# MSP430G2553 register map
Registers are 8-bit, read-write, reset 0x0 unless marked. A register's access mark holds for its fields unless they carry their own. Offsets are from the block's base; [hi:lo] are bit positions; {n}, {i} and the like mark numbered series.

## CALIBRATION_DATA
Base 0x000010F8
0x00 CALDCO_16MHZ — DCOCTL Calibration Data for 16MHz
0x01 CALBC1_16MHZ — BCSCTL1 Calibration Data for 16MHz
0x02 CALDCO_12MHZ — DCOCTL Calibration Data for 12MHz
0x03 CALBC1_12MHZ — BCSCTL1 Calibration Data for 12MHz
0x04 CALDCO_8MHZ — DCOCTL Calibration Data for 8MHz
0x05 CALBC1_8MHZ — BCSCTL1 Calibration Data for 8MHz
0x06 CALDCO_1MHZ — DCOCTL Calibration Data for 1MHz
0x07 CALBC1_1MHZ — BCSCTL1 Calibration Data for 1MHz

## TIMER_1_A3
Base 0x0000011E
0x00 TA1IV 16-bit — Timer1_A3 Interrupt Vector Word
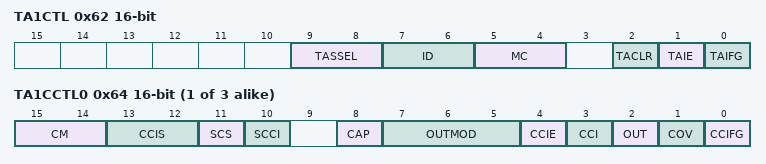
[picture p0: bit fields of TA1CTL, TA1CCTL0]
0x62 TA1CTL 16-bit — Timer1_A3 Control
  [9:8] TASSEL — Timer A clock source select 1
    0=Timer A clock source select: 0 - TACLK; 1=Timer A clock source select: 1 - ACLK; 2=Timer A clock source select: 2 - SMCLK; 3=Timer A clock source select: 3 - INCLK
  [7:6] ID — Timer A clock input divider 1
    0=Timer A input divider: 0 - /1; 1=Timer A input divider: 1 - /2; 2=Timer A input divider: 2 - /4; 3=Timer A input divider: 3 - /8
  [5:4] MC — Timer A mode control 1
    0=Timer A mode control: 0 - Stop; 1=Timer A mode control: 1 - Up to CCR0; 2=Timer A mode control: 2 - Continous up; 3=Timer A mode control: 3 - Up/Down
  [2] TACLR — Timer A counter clear
  [1] TAIE — Timer A counter interrupt enable
  [0] TAIFG — Timer A counter interrupt flag
{0x64+2i} TA1CCTL{i} 16-bit (i=0..2) — Timer1_A3 Capture/Compare Control {i}
  [15:14] CM — Capture mode 1
    0=Capture mode: 0 - disabled; 1=Capture mode: 1 - pos. edge; 2=Capture mode: 1 - neg. edge; 3=Capture mode: 1 - both edges
  [13:12] CCIS — Capture input select 1
    0=Capture input select: 0 - CCIxA; 1=Capture input select: 1 - CCIxB; 2=Capture input select: 2 - GND; 3=Capture input select: 3 - Vcc
  [11] SCS — Capture sychronize
  [10] SCCI — Latched capture signal (read)
  [8] CAP — Capture mode: 1 /Compare mode : 0
  [7:5] OUTMOD — Output mode 2
    0=PWM output mode: 0 - output only; 1=PWM output mode: 1 - set; 2=PWM output mode: 2 - PWM toggle/reset; 3=PWM output mode: 3 - PWM set/reset; 4=PWM output mode: 4 - toggle; 5=PWM output mode: 5 - Reset; 6=PWM output mode: 6 - PWM toggle/set; 7=PWM output mode: 7 - PWM reset/set
  [4] CCIE — Capture/compare interrupt enable
  [3] CCI — Capture input signal (read)
  [2] OUT — PWM Output signal if output mode 0
  [1] COV — Capture/compare overflow flag
  [0] CCIFG — Capture/compare interrupt flag
0x72 TA1R 16-bit — Timer1_A3 Counter Register
{0x74+2i} TA1CCR{i} 16-bit (i=0..2) — Timer1_A3 Capture/Compare {i}

## WATCHDOG_TIMER
Base 0x00000120
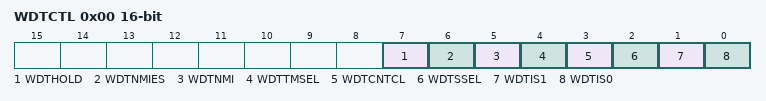
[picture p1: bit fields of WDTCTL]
0x00 WDTCTL 16-bit — Watchdog Timer Control
  [7] WDTHOLD, [6] WDTNMIES, [5] WDTNMI, [4] WDTTMSEL, [3] WDTCNTCL, [2] WDTSSEL, [1] WDTIS1, [0] WDTIS0

## FLASH
Base 0x00000128
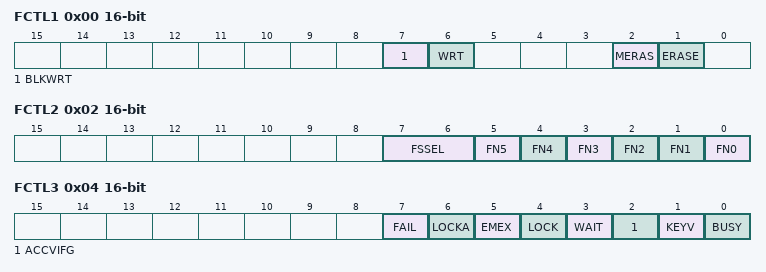
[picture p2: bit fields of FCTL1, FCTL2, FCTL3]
0x00 FCTL1 16-bit — FLASH Control 1
  [7] BLKWRT — Enable bit for Flash segment write
  [6] WRT — Enable bit for Flash write
  [2] MERAS — Enable bit for Flash mass erase
  [1] ERASE — Enable bit for Flash segment erase
0x02 FCTL2 16-bit — FLASH Control 2
  [7:6] FSSEL — Flash clock select 0 */ /* to distinguish from USART SSELx
    0=Flash clock select: 0 - ACLK; 1=Flash clock select: 1 - MCLK; 2=Flash clock select: 2 - SMCLK; 3=Flash clock select: 3 - SMCLK
  [n] FN{n} (n=2..5)
  [1] FN1 — 32*FN5 + 16*FN4 + 8*FN3 + 4*FN2 + 2*FN1 + FN0 + 1
  [0] FN0 — Divide Flash clock by 1 to 64 using FN0 to FN5 according to:
0x04 FCTL3 16-bit — FLASH Control 3
  [7] FAIL — Last Program or Erase failed
  [6] LOCKA — Segment A Lock bit: read = 1 - Segment is locked (read only)
  [5] EMEX — Flash Emergency Exit
  [4] LOCK — Lock bit: 1 - Flash is locked (read only)
  [3] WAIT — Wait flag for segment write
  [2] ACCVIFG — Flash Access violation flag
  [1] KEYV — Flash Key violation flag
  [0] BUSY — Flash busy: 1

## TIMER_0_A3
Base 0x0000012E
0x00 TA0IV 16-bit — Timer0_A3 Interrupt Vector Word
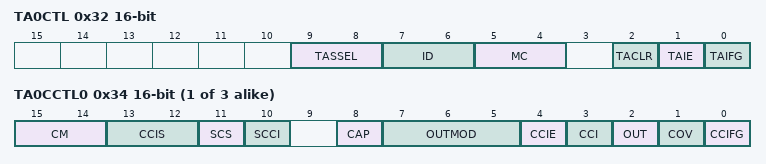
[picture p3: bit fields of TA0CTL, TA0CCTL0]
0x32 TA0CTL 16-bit — Timer0_A3 Control
  [9:8] TASSEL — Timer A clock source select 1
    0=Timer A clock source select: 0 - TACLK; 1=Timer A clock source select: 1 - ACLK; 2=Timer A clock source select: 2 - SMCLK; 3=Timer A clock source select: 3 - INCLK
  [7:6] ID — Timer A clock input divider 1
    0=Timer A input divider: 0 - /1; 1=Timer A input divider: 1 - /2; 2=Timer A input divider: 2 - /4; 3=Timer A input divider: 3 - /8
  [5:4] MC — Timer A mode control 1
    0=Timer A mode control: 0 - Stop; 1=Timer A mode control: 1 - Up to CCR0; 2=Timer A mode control: 2 - Continous up; 3=Timer A mode control: 3 - Up/Down
  [2] TACLR — Timer A counter clear
  [1] TAIE — Timer A counter interrupt enable
  [0] TAIFG — Timer A counter interrupt flag
{0x34+2i} TA0CCTL{i} 16-bit (i=0..2) — Timer0_A3 Capture/Compare Control {i}
  [15:14] CM — Capture mode 1
    0=Capture mode: 0 - disabled; 1=Capture mode: 1 - pos. edge; 2=Capture mode: 1 - neg. edge; 3=Capture mode: 1 - both edges
  [13:12] CCIS — Capture input select 1
    0=Capture input select: 0 - CCIxA; 1=Capture input select: 1 - CCIxB; 2=Capture input select: 2 - GND; 3=Capture input select: 3 - Vcc
  [11] SCS — Capture sychronize
  [10] SCCI — Latched capture signal (read)
  [8] CAP — Capture mode: 1 /Compare mode : 0
  [7:5] OUTMOD — Output mode 2
    0=PWM output mode: 0 - output only; 1=PWM output mode: 1 - set; 2=PWM output mode: 2 - PWM toggle/reset; 3=PWM output mode: 3 - PWM set/reset; 4=PWM output mode: 4 - toggle; 5=PWM output mode: 5 - Reset; 6=PWM output mode: 6 - PWM toggle/set; 7=PWM output mode: 7 - PWM reset/set
  [4] CCIE — Capture/compare interrupt enable
  [3] CCI — Capture input signal (read)
  [2] OUT — PWM Output signal if output mode 0
  [1] COV — Capture/compare overflow flag
  [0] CCIFG — Capture/compare interrupt flag
0x42 TA0R 16-bit — Timer0_A3 Counter Register
{0x44+2i} TA0CCR{i} 16-bit (i=0..2) — Timer0_A3 Capture/Compare {i}
